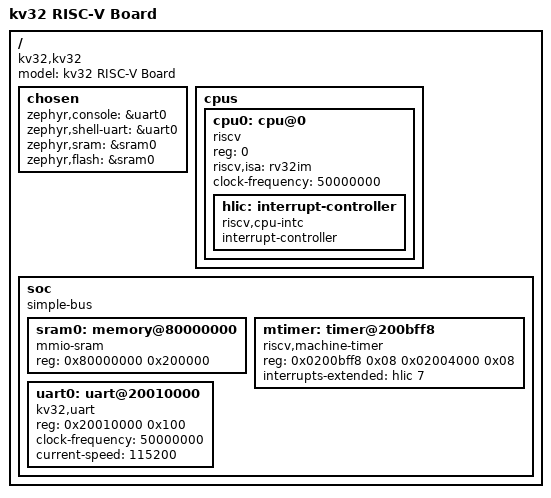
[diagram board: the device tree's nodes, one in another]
/*
 * Copyright (c) 2026 kv32 Project
 * SPDX-License-Identifier: Apache-2.0
 */

/dts-v1/;

#include <zephyr/dt-bindings/gpio/gpio.h>

/ {
    model = "kv32 RISC-V Board";
    compatible = "kv32,kv32";
    #address-cells = <1>;
    #size-cells = <1>;

    chosen {
        zephyr,console = &uart0;
        zephyr,shell-uart = &uart0;
        zephyr,sram = &sram0;
        zephyr,flash = &sram0;
    };

    cpus {
        #address-cells = <1>;
        #size-cells = <0>;

        cpu0: cpu@0 {
            device_type = "cpu";
            compatible = "riscv";
            reg = <0>;
            riscv,isa = "rv32im";
            clock-frequency = <50000000>;

            hlic: interrupt-controller {
                compatible = "riscv,cpu-intc";
                #interrupt-cells = <1>;
                interrupt-controller;
            };
        };
    };

    soc {
        #address-cells = <1>;
        #size-cells = <1>;
        compatible = "simple-bus";
        ranges;

        sram0: memory@80000000 {
            compatible = "mmio-sram";
            reg = <0x80000000 0x200000>;  /* 2MB */
        };

        mtimer: timer@200bff8 {
            compatible = "riscv,machine-timer";
            reg = <0x0200bff8 0x08    /* mtime */
                   0x02004000 0x08>;  /* mtimecmp */
            reg-names = "mtime", "mtimecmp";
            interrupts-extended = <&hlic 7>;
        };

        uart0: uart@20010000 {
            compatible = "kv32,uart";
            reg = <0x20010000 0x100>;
            clock-frequency = <50000000>;
            current-speed = <115200>;
            status = "okay";
        };
    };
};
